VERSION ""

NS_ :

BS_:

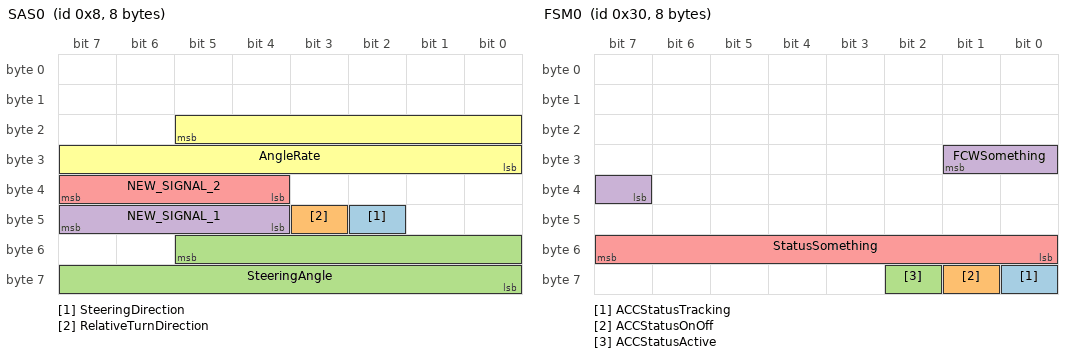
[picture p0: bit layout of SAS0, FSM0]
BO_ 8 SAS0: 8 SAS
 SG_ SteeringDirection : 42|1@0+ (1,0) [0|1] "" XXX
 SG_ RelativeTurnDirection : 43|1@0+ (1,0) [0|1] "" XXX
 SG_ SteeringAngle : 53|14@0+ (0.04395,0) [0|65535] "degrees" XXX
 SG_ NEW_SIGNAL_1 : 47|4@0+ (1,0) [0|15] "" XXX
 SG_ NEW_SIGNAL_2 : 39|4@0+ (1,0) [0|15] "" XXX
 SG_ AngleRate : 21|14@0+ (0.075,0) [0|1500] "deg/S" XXX

BO_ 16 CCButtons: 8 CEM
 SG_ byte0 : 7|8@0+ (1,0) [0|255] "" XXX
 SG_ byte1 : 15|8@0+ (1,0) [0|255] "" XXX
 SG_ byte2 : 23|8@0+ (1,0) [0|255] "" XXX
 SG_ byte3 : 31|8@0+ (1,0) [0|255] "" XXX
 SG_ byte4 : 39|8@0+ (1,0) [0|255] "" XXX
 SG_ byte6 : 55|5@0+ (1,0) [0|31] "" XXX
 SG_ B7b0 : 56|1@0+ (1,0) [0|1] "" XXX
 SG_ B7b1 : 57|1@0+ (1,0) [0|1] "" XXX
 SG_ B7b6 : 62|1@0+ (1,0) [0|1] "" XXX
 SG_ ACCOnOffBtn : 58|1@0+ (1,0) [0|1] "" XXX
 SG_ ACCSetBtn : 63|1@0+ (1,0) [0|1] "" XXX
 SG_ ACCStopBtn : 60|1@0+ (1,0) [0|1] "" XXX
 SG_ ACCResumeBtn : 61|1@0+ (1,0) [0|1] "" XXX
 SG_ ACCMinusBtn : 48|1@0+ (1,0) [0|1] "" XXX
 SG_ TimeGapIncreaseBtn : 49|1@0+ (1,0) [0|1] "" XXX
 SG_ TimeGapDecreaseBtn : 50|1@0+ (1,0) [0|1] "" XXX
 SG_ byte5 : 47|8@0+ (1,0) [0|255] "" XXX
 SG_ B7b3 : 59|1@0+ (1,0) [0|1] "" XXX

BO_ 48 FSM0: 8 FSM
 SG_ ACCStatusTracking : 56|1@0+ (1,0) [0|1] "" XXX
 SG_ ACCStatusOnOff : 57|1@0+ (1,0) [0|1] "" XXX
 SG_ ACCStatusActive : 58|1@0+ (1,0) [0|1] "" XXX
 SG_ FCWSomething : 25|3@0+ (1,0) [0|3] "" XXX
 SG_ StatusSomething : 55|8@0+ (1,0) [0|255] "" XXX

BO_ 64 TCM0: 8 TCM
 SG_ RPMSomething : 42|11@0+ (1,0) [0|2047] "" XXX
 SG_ GearShifter : 46|2@0+ (1,0) [0|3] "" XXX

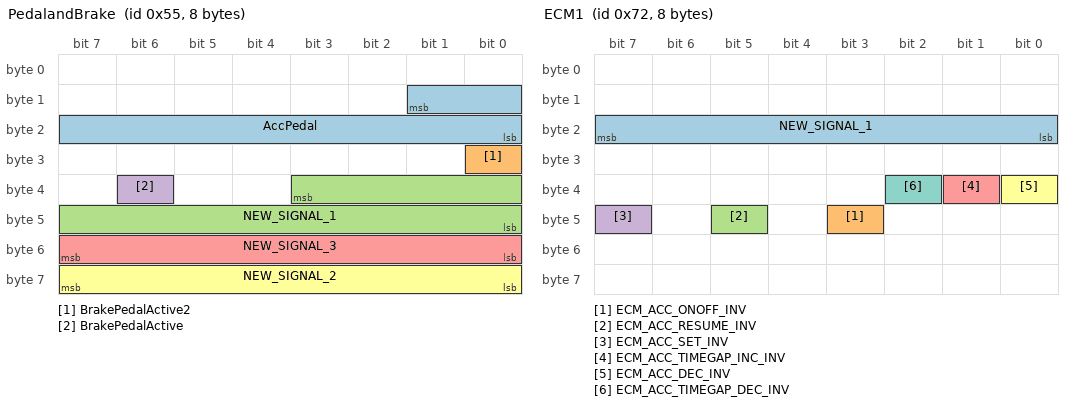
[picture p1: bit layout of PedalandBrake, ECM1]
BO_ 85 PedalandBrake: 8 ECM
 SG_ AccPedal : 9|10@0+ (0.1,0) [0|1023] "%" XXX
 SG_ BrakePedalActive2 : 24|1@0+ (1,0) [0|1] "" XXX
 SG_ NEW_SIGNAL_1 : 35|12@0+ (1,0) [0|4095] "" XXX
 SG_ BrakePedalActive : 38|1@0+ (1,0) [0|1] "" XXX
 SG_ NEW_SIGNAL_3 : 55|8@0+ (1,0) [0|255] "" XXX
 SG_ NEW_SIGNAL_2 : 63|8@0+ (1,0) [0|255] "" XXX

BO_ 101 EngineInfo: 8 XXX
 SG_ NEW_SIGNAL_1 : 17|10@0+ (1,-512) [0|1023] "" XXX
 SG_ EngineSpeed : 52|13@0+ (1,0) [0|1023] "" XXX

BO_ 112 NEW_MSG_4: 8 XXX
 SG_ NEW_SIGNAL_1 : 39|8@0+ (1,0) [0|255] "" XXX

BO_ 114 ECM1: 8 ECM1
 SG_ NEW_SIGNAL_1 : 23|8@0+ (1,0) [0|255] "" XXX
 SG_ ECM_ACC_ONOFF_INV : 43|1@0+ (1,0) [0|1] "" XXX
 SG_ ECM_ACC_RESUME_INV : 45|1@0+ (1,0) [0|1] "" XXX
 SG_ ECM_ACC_SET_INV : 47|1@0+ (1,0) [0|1] "" XXX
 SG_ ECM_ACC_TIMEGAP_INC_INV : 33|1@0+ (1,0) [0|1] "" XXX
 SG_ ECM_ACC_DEC_INV : 32|1@0+ (1,0) [0|1] "" XXX
 SG_ ECM_ACC_TIMEGAP_DEC_INV : 34|1@0+ (1,0) [0|1] "" XXX

BO_ 117 ECM1_2: 8 ECM

BO_ 128 NEW_MSG_5: 8 XXX
 SG_ NEW_SIGNAL_2 : 26|11@0+ (1,0) [0|2047] "" XXX
 SG_ NEW_SIGNAL_1 : 52|13@0+ (1,0) [0|8191] "" XXX

BO_ 176 ECM2: 8 ECM
 SG_ NEW_SIGNAL_1 : 50|11@0+ (1,0) [0|2047] "" XXX
 SG_ NEW_SIGNAL_2 : 47|8@0+ (1,0) [0|63] "" XXX

BO_ 192 Gear: 8 XXX
 SG_ TransmissionGear : 36|3@0+ (1,1) [0|7] "" XXX

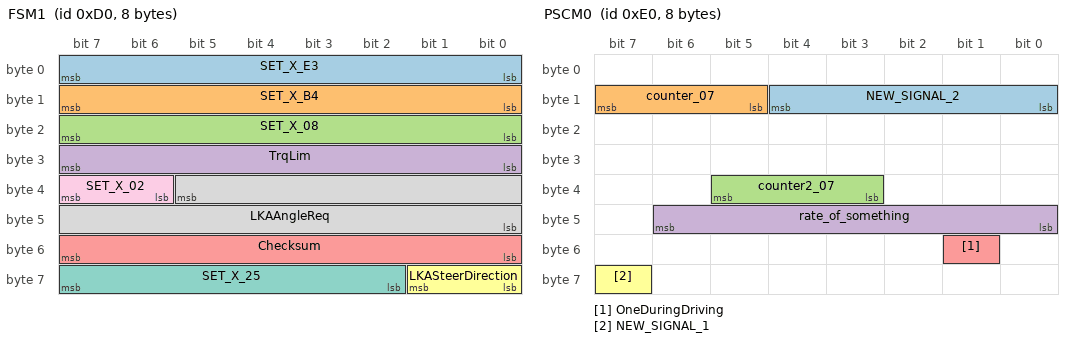
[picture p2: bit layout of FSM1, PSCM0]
BO_ 208 FSM1: 8 FSM
 SG_ SET_X_E3 : 7|8@0+ (1,0) [0|255] "" XXX
 SG_ SET_X_B4 : 15|8@0+ (1,0) [0|255] "" XXX
 SG_ SET_X_08 : 23|8@0+ (1,0) [0|255] "" XXX
 SG_ TrqLim : 31|8@0+ (1,-128) [0|255] "" XXX
 SG_ Checksum : 55|8@0+ (1,0) [0|255] "" XXX
 SG_ LKASteerDirection : 57|2@0+ (1,0) [0|2] "" XXX
 SG_ SET_X_25 : 63|6@0+ (1,0) [0|63] "" XXX
 SG_ LKAAngleReq : 37|14@0+ (0.04395,-360.0384) [-360.0384|359.99445] "degrees" XXX
 SG_ SET_X_02 : 39|2@0+ (1,0) [0|3] "" XXX

BO_ 224 PSCM0: 8 PSCM
 SG_ NEW_SIGNAL_2 : 12|5@0+ (1,0) [0|31] "" XXX
 SG_ counter_07 : 15|3@0+ (1,0) [0|7] "" XXX
 SG_ counter2_07 : 37|3@0+ (1,0) [0|16383] "" XXX
 SG_ rate_of_something : 46|7@0+ (1,0) [0|62] "" XXX
 SG_ OneDuringDriving : 49|1@0+ (1,0) [0|1] "" XXX
 SG_ NEW_SIGNAL_1 : 63|1@0+ (1,0) [0|1] "" XXX

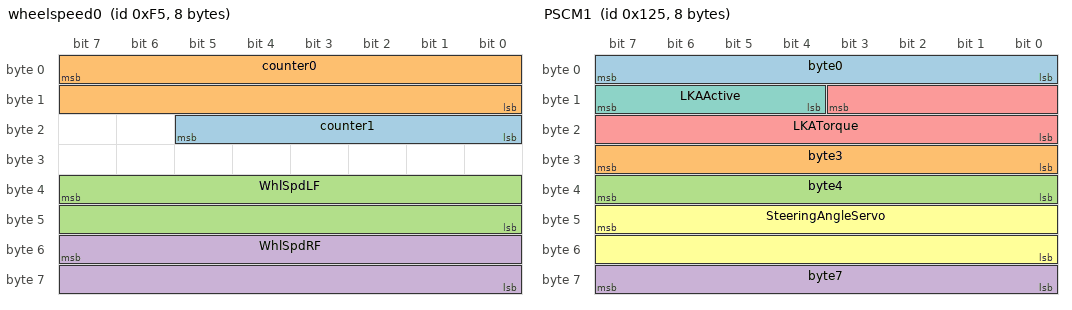
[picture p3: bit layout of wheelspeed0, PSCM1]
BO_ 245 wheelspeed0: 8 BCM
 SG_ counter1 : 21|6@0+ (1,0) [0|65535] "" XXX
 SG_ counter0 : 7|16@0+ (1,0) [0|65535] "" XXX
 SG_ WhlSpdLF : 39|16@0+ (1,0) [0|65535] "" XXX
 SG_ WhlSpdRF : 55|16@0+ (1,0) [0|65535] "" XXX

BO_ 272 SpeedSignal0: 8 XXX
 SG_ VehicleSpeedSignal : 55|16@0+ (0.01,0) [0|65535] "" XXX

BO_ 288 wheel_speed1: 8 BCM
 SG_ WhlSpdLR : 39|16@0+ (1,0) [0|65535] "" XXX
 SG_ WhlSpdRR : 55|16@0+ (1,0) [0|65535] "" XXX

BO_ 293 PSCM1: 8 PSCM
 SG_ byte0 : 7|8@0+ (1,0) [0|255] "" XXX
 SG_ byte3 : 31|8@0+ (1,0) [0|255] "" XXX
 SG_ byte4 : 39|8@0+ (1,0) [0|255] "" XXX
 SG_ byte7 : 63|8@0+ (1,0) [0|255] "" XXX
 SG_ LKATorque : 11|12@0+ (1,-2000) [0|4095] "" XXX
 SG_ SteeringAngleServo : 47|16@0+ (0.04395,-1440.1536) [0|65535] "deg" XXX
 SG_ LKAActive : 15|4@0+ (1,0) [0|15] "" XXX

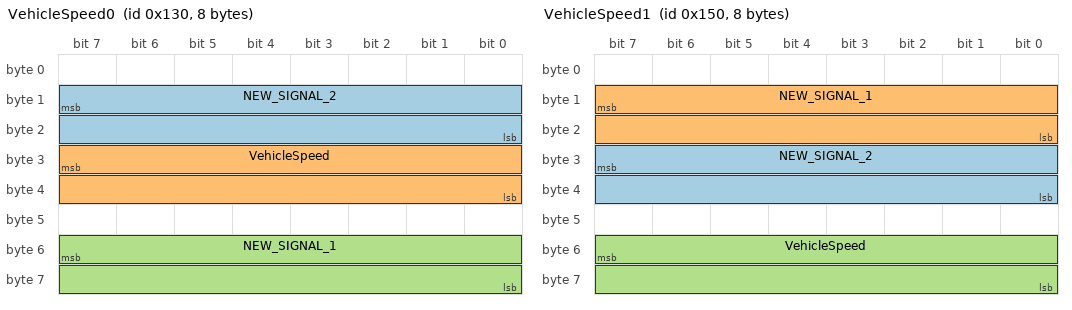
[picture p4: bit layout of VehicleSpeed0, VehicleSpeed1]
BO_ 304 VehicleSpeed0: 8 BCM
 SG_ NEW_SIGNAL_2 : 15|16@0+ (1,0) [0|65535] "" XXX
 SG_ VehicleSpeed : 31|16@0+ (0.01,0) [0|65535] "km/h" XXX
 SG_ NEW_SIGNAL_1 : 55|16@0+ (1,0) [0|65535] "" XXX

BO_ 325 ECM3: 8 ECM

BO_ 336 VehicleSpeed1: 8 BCM
 SG_ NEW_SIGNAL_2 : 31|16@0+ (1,0) [0|65535] "" XXX
 SG_ NEW_SIGNAL_1 : 15|16@0+ (1,0) [0|65535] "" XXX
 SG_ VehicleSpeed : 55|16@0+ (0.01,0) [0|65535] "" XXX

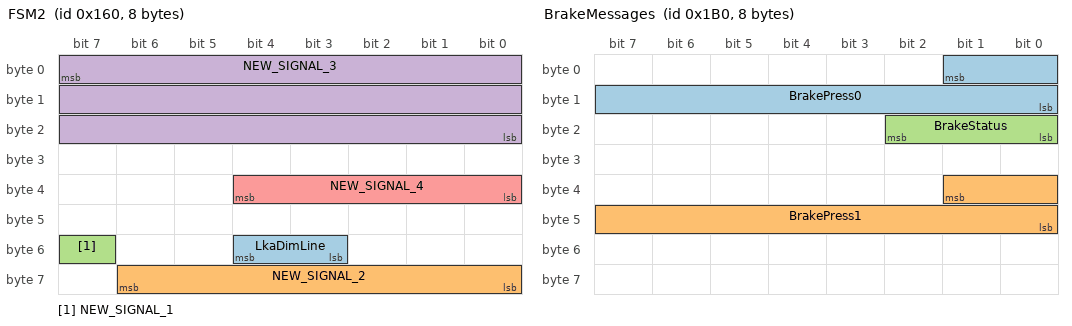
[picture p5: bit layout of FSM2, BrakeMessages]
BO_ 352 FSM2: 8 FSM
 SG_ LkaDimLine : 51|2@1+ (1,0) [0|127] "" XXX
 SG_ NEW_SIGNAL_2 : 56|7@1+ (1,0) [0|255] "" XXX
 SG_ NEW_SIGNAL_1 : 55|1@0+ (1,0) [0|1] "" XXX
 SG_ NEW_SIGNAL_3 : 7|24@0+ (1,0) [0|16777215] "" XXX
 SG_ NEW_SIGNAL_4 : 36|5@0+ (1,0) [0|31] "" XXX

BO_ 432 BrakeMessages: 8 BCM
 SG_ BrakePress0 : 1|10@0+ (1,0) [0|1023] "" XXX
 SG_ BrakePress1 : 33|10@0+ (1,0) [0|1023] "" XXX
 SG_ BrakeStatus : 18|3@0+ (1,0) [0|7] "" XXX

BO_ 464 DIM0: 8 DIM

BO_ 480 BCM0: 8 BCM

BO_ 528 CEM0: 8 CEM

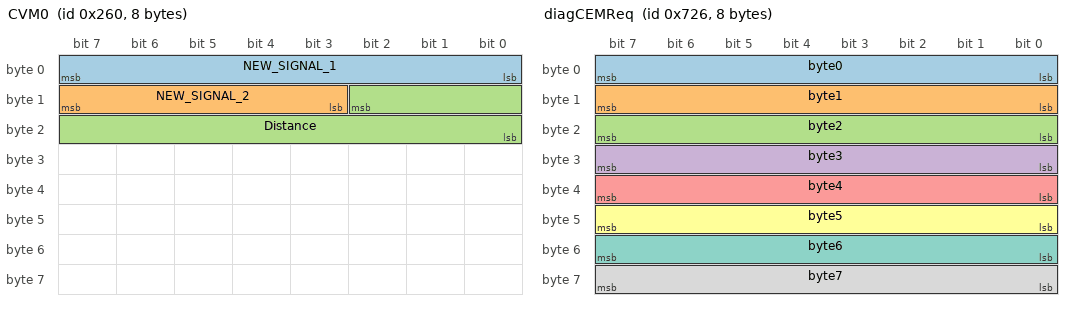
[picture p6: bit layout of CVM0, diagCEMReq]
BO_ 608 CVM0: 8 CVM
 SG_ NEW_SIGNAL_1 : 7|8@0+ (1,0) [0|255] "" XXX
 SG_ NEW_SIGNAL_2 : 15|5@0+ (1,0) [0|32] "" XXX
 SG_ Distance : 10|11@0+ (1,0) [0|2048] "" XXX

BO_ 624 FSM3: 8 FSM
 SG_ NEW_SIGNAL_1 : 23|8@0+ (1,0) [0|255] "" XXX

BO_ 640 FSM4: 8 FSM
 SG_ SpeedTarget : 47|8@0+ (1,0) [0|255] "" XXX
 SG_ NEW_SIGNAL_1 : 49|10@0+ (1,0) [0|255] "" XXX

BO_ 648 SRS0: 8 SRS

BO_ 652 ECM4: 8 ECM

BO_ 656 ECM5: 8 ECM

BO_ 657 ECM6: 8 ECM

BO_ 681 MiscCarInfo: 8 CEM
 SG_ TurnSignal : 1|2@0+ (1,0) [0|3] "" XXX
 SG_ HighBeamOn : 52|1@0+ (1,0) [0|1] "" XX

BO_ 693 ECM7: 8 ECM

BO_ 709 ACC: 8 ECM
 SG_ SpeedTargetACC : 0|9@0+ (0.5,0) [0|511] "" XXX

BO_ 853 FSM5: 8 FSM
 SG_ TargetSpeedOdo : 23|8@0+ (1,0) [0|63] "kph" XXX
 SG_ SpeedSign : 36|5@0+ (5,0) [0|32] "" XXX
 SG_ TextUnderSign : 37|1@0+ (1,0) [0|1] "" XXX
 SG_ NEW_SIGNAL_6 : 39|3@0+ (1,0) [0|3] "" XXX
 SG_ NEW_SIGNAL_5 : 47|8@0+ (1,0) [0|255] "" XXX
 SG_ NEW_SIGNAL_3 : 31|8@0+ (1,0) [0|255] "" XXX
 SG_ LaneMarkingsOdo : 15|4@0+ (1,0) [0|7] "" XXX
 SG_ NEW_SIGNAL_2 : 11|4@0+ (1,0) [0|15] "" XXX
 SG_ NEW_SIGNAL_1 : 7|8@0+ (1,0) [0|255] "" XXX
 SG_ NEW_SIGNAL_4 : 55|16@0+ (1,0) [0|65535] "" XXX

BO_ 864 CEM1: 8 CEM

BO_ 912 DIM1: 8 DIM

BO_ 968 SRS1: 8 SRS
 SG_ PassengerSeatBelt : 22|1@0+ (1,0) [0|1] "" XXX
 SG_ DriverSeatBelt : 19|1@0+ (1,0) [0|1] "" XXX

BO_ 1029 CEMBCM0: 8 CEM

BO_ 1344 NEW_MSG_1: 8 XXX
 SG_ NEW_SIGNAL_1 : 4|13@0+ (1,0) [0|8191] "" XXX

BO_ 1830 diagCEMReq: 8 XXX
 SG_ byte0 : 7|8@0+ (1,0) [0|255] "" XXX
 SG_ byte1 : 15|8@0+ (1,0) [0|255] "" XXX
 SG_ byte2 : 23|8@0+ (1,0) [0|255] "" XXX
 SG_ byte3 : 31|8@0+ (1,0) [0|255] "" XXX
 SG_ byte4 : 39|8@0+ (1,0) [0|255] "" XXX
 SG_ byte5 : 47|8@0+ (1,0) [0|255] "" XXX
 SG_ byte6 : 55|8@0+ (1,0) [0|255] "" XXX
 SG_ byte7 : 63|8@0+ (1,0) [0|255] "" XXX

BO_ 1838 diagCEMResp: 8 XXX
 SG_ byte03 : 7|32@0+ (1,0) [0|4294967295] "" XXX
 SG_ byte47 : 39|32@0+ (1,0) [0|4294967295] "" XXX

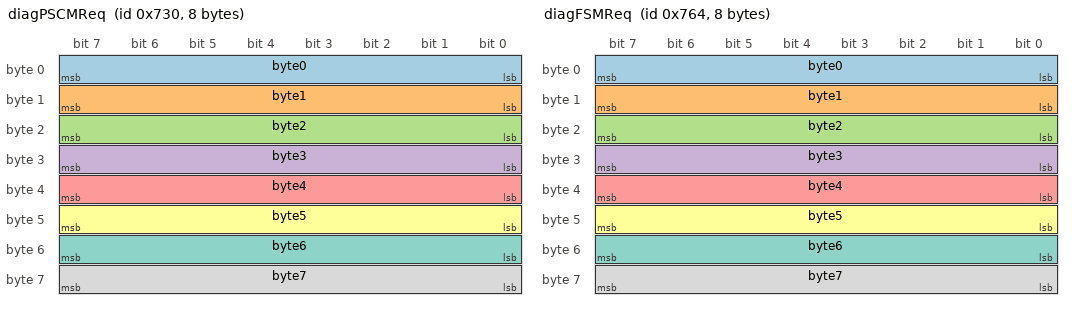
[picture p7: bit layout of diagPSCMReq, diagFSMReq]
BO_ 1840 diagPSCMReq: 8 XXX
 SG_ byte0 : 7|8@0+ (1,0) [0|255] "" XXX
 SG_ byte1 : 15|8@0+ (1,0) [0|255] "" XXX
 SG_ byte2 : 23|8@0+ (1,0) [0|255] "" XXX
 SG_ byte3 : 31|8@0+ (1,0) [0|255] "" XXX
 SG_ byte4 : 39|8@0+ (1,0) [0|255] "" XXX
 SG_ byte5 : 47|8@0+ (1,0) [0|255] "" XXX
 SG_ byte6 : 55|8@0+ (1,0) [0|255] "" XXX
 SG_ byte7 : 63|8@0+ (1,0) [0|255] "" XXX

BO_ 1848 diagPSCMResp: 8 XXX
 SG_ byte03 : 7|32@0+ (1,0) [0|4294967295] "" XXX
 SG_ byte47 : 39|32@0+ (1,0) [0|4294967295] "" XXX

BO_ 1892 diagFSMReq: 8 XXX
 SG_ byte0 : 7|8@0+ (1,0) [0|255] "" XXX
 SG_ byte1 : 15|8@0+ (1,0) [0|255] "" XXX
 SG_ byte2 : 23|8@0+ (1,0) [0|255] "" XXX
 SG_ byte3 : 31|8@0+ (1,0) [0|255] "" XXX
 SG_ byte4 : 39|8@0+ (1,0) [0|255] "" XXX
 SG_ byte5 : 47|8@0+ (1,0) [0|255] "" XXX
 SG_ byte6 : 55|8@0+ (1,0) [0|255] "" XXX
 SG_ byte7 : 63|8@0+ (1,0) [0|255] "" XXX

BO_ 1900 diagFSMResp: 8 XXX
 SG_ byte03 : 7|32@0+ (1,0) [0|4294967295] "" XXX
 SG_ byte47 : 39|32@0+ (1,0) [0|4294967295] "" XXX

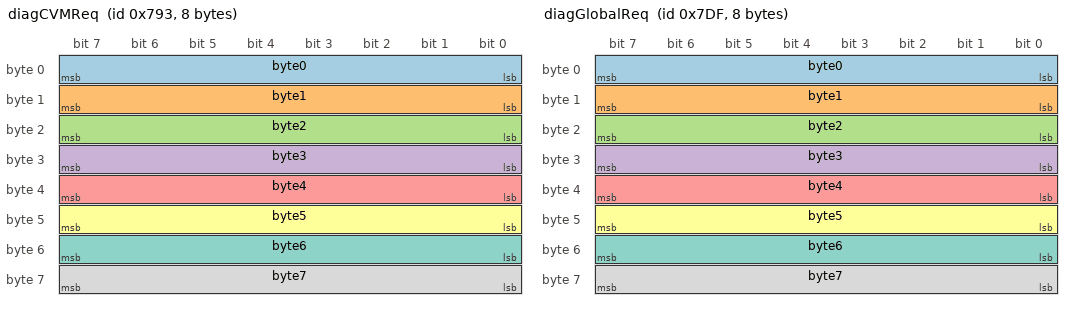
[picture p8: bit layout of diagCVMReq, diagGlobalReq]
BO_ 1939 diagCVMReq: 8 XXX
 SG_ byte0 : 7|8@0+ (1,0) [0|255] "" XXX
 SG_ byte1 : 15|8@0+ (1,0) [0|255] "" XXX
 SG_ byte2 : 23|8@0+ (1,0) [0|255] "" XXX
 SG_ byte3 : 31|8@0+ (1,0) [0|255] "" XXX
 SG_ byte4 : 39|8@0+ (1,0) [0|255] "" XXX
 SG_ byte5 : 47|8@0+ (1,0) [0|255] "" XXX
 SG_ byte6 : 55|8@0+ (1,0) [0|255] "" XXX
 SG_ byte7 : 63|8@0+ (1,0) [0|255] "" XXX

BO_ 1947 diagCVMResp: 8 XXX
 SG_ byte03 : 7|32@0+ (1,0) [0|4294967295] "" XXX
 SG_ byte47 : 39|32@0+ (1,0) [0|4294967295] "" XXX

BO_ 2015 diagGlobalReq: 8 XXX
 SG_ byte0 : 7|8@0+ (1,0) [0|255] "" XXX
 SG_ byte1 : 15|8@0+ (1,0) [0|255] "" XXX
 SG_ byte2 : 23|8@0+ (1,0) [0|255] "" XXX
 SG_ byte3 : 31|8@0+ (1,0) [0|255] "" XXX
 SG_ byte4 : 39|8@0+ (1,0) [0|255] "" XXX
 SG_ byte5 : 47|8@0+ (1,0) [0|255] "" XXX
 SG_ byte6 : 55|8@0+ (1,0) [0|255] "" XXX
 SG_ byte7 : 63|8@0+ (1,0) [0|255] "" XXX

BU_: XXX

CM_ SG_ 1104 DRIVER_SEAT_BELT_ONOFF "0 - on , 1 = off";
CM_ SG_ 1056 DOOR_RL_STATUS "04 - RL - open";
CM_ SG_ 1056 DOOR_FL_STATUS "28 - FL open , 38 - FR";
CM_ SG_ 1056 RIGHT_SIGNAL_STATUS "R,L shows at same time means hazard";
CM_ SG_ 832 TRANS_MODE "AT - 85 / MT - 8D";
CM_ SG_ 832 TRANS_GEAR_POS "R-7 , 0 - N";
CM_ SG_ 821 CRUSE_ONOFF "Cruse Switch";
CM_ SG_ 821 CRUSE_ENABLED "Cruse enabled";
CM_ SG_ 821 THROTTLE_PEDAL_POS "Real Pedal Pos";
CM_ SG_ 821 THROTTLE_POS "Throttle Pos for Cruse Mode";
CM_ SG_ 906 ABS_UNDEF1 "ABS force";
CM_ SG_ 906 SPEED_FL "used for car speed in dash board";
VAL_ 513 STATE 5 "FAULT_TIMEOUT" 4 "FAULT_STARTUP" 3 "FAULT_SCE" 2 "FAULT_SEND" 1 "FAULT_BAD_CHECKSUM" 0 "NO_FAULT" ;

VAL_ 295 GEAR 0 "P" 1 "R" 2 "N" 3 "D" 4 "B";
VAL_ 466 CRUISE_STATE 11 "timer_3sec" 10 "adaptive click down" 9 "adaptive click up" 8 "adaptive engaged" 7 "standstill" 6 "non-adaptive click up" 5 "non-adaptive click down" 4 "non-adaptive hold down" 3 "non-adaptive hold up" 2 "non-adaptive being engaged" 1 "non-adaptive engaged" 0 "off";
VAL_ 467 LOW_SPEED_LOCKOUT 2 "low speed locked" 1 "ok";
VAL_ 467 PCM_FOLLOW_DISTANCE 1 "far" 2 "medium" 3 "close";
VAL_ 614 STATE 3 "enabled" 1 "disabled";
VAL_ 614 DIRECTION_CMD 3 "right" 2 "center" 1 "left";
VAL_ 643 STATE 0 "normal" 1 "adaptive_cruise_control" 3 "emergency_braking";
VAL_ 835 ACC_TYPE 2 "permanent low speed lockout" 1 "ok";
VAL_ 835 ACC_MALFUNCTION 1 "faulted" 0 "ok";
VAL_ 835 ACC_CUT_IN 1 "CUT-IN Detected" 0 "clear";
VAL_ 835 ALLOW_LONG_PRESS 2 "set speed increase by 5 speed units regardless" 1 "set speed increase by 1 speed unit on short press, 5 speed units on long press";
VAL_ 865 CLUTCH_RELEASED 0 "clutch pressed any amount" 1 "clutch released"
VAL_ 921 CRUISE_CONTROL_STATE 2 "disabled" 11 "hold" 10 "hold_waiting_user_cmd" 6 "enabled" 5 "faulted";
VAL_ 956 SPORT_ON 0 "off" 1 "on";
VAL_ 956 GEAR 0 "D" 1 "S" 8 "N" 16 "R" 32 "P";
VAL_ 956 SPORT_GEAR_ON 0 "off" 1 "on";
VAL_ 956 SPORT_GEAR 1 "S1" 2 "S2" 3 "S3" 4 "S4" 5 "S5" 6 "S6";
VAL_ 956 ECON_ON 0 "off" 1 "on";
VAL_ 956 B_GEAR_ENGAGED 0 "off" 1 "on";
VAL_ 956 DRIVE_ENGAGED 0 "off" 1 "on";
VAL_ 1005 REVERSE_CAMERA_GUIDELINES 3 "No guidelines" 2 "Static guidelines" 1 "Active guidelines";
VAL_ 1009 PCM_FOLLOW_DISTANCE 1 "far" 2 "medium" 3 "close";
VAL_ 1041 PCS_INDICATOR 2 "PCS Faulted" 1 "PCS Turned Off By User" 0 "PCS Enabled";
VAL_ 1041 PCS_SENSITIVITY 64 "high sensitivity"  128 "mid sensitivity" 192 "low sensitivity" 0 "off";
VAL_ 1042 LDA_ALERT 3 "hold with continuous beep" 2 "LDA unavailable" 1 "hold" 0 "none";
VAL_ 1042 BARRIERS 3 "left" 2 "right" 1 "both" 0 "none";
VAL_ 1042 RIGHT_LINE 3 "orange" 2 "faded" 1 "solid" 0 "none";
VAL_ 1042 LKAS_STATUS 1 "on" 0 "off";
VAL_ 1042 LEFT_LINE 3 "orange" 2 "faded" 1 "solid" 0 "none";
VAL_ 1042 LDA_ON_MESSAGE 2 "Lane Departure Alert Turned ON, Steering Assist Inactive" 1 "Lane Departure Alert Turned ON, Steering Assist Active" 0 "clear";
VAL_ 1042 LDA_SA_TOGGLE  2 "steering assist off" 1 "steering assist on";
VAL_ 1042 LDA_SENSITIVITY 2 "standard" 1 "high" 0 "undefined";
VAL_ 1042 LDA_MESSAGES 4 "lda unavailable at this speed" 1 "lda unavailable below approx 50km/h" 0 "ok";
VAL_ 1042 LDA_FRONT_CAMERA_BLOCKED 1 "lda unavailable" 0 "ok";
VAL_ 1042 TAKE_CONTROL 1 "take control" 0 "ok";
VAL_ 1042 LANE_SWAY_WARNING 3 "ok" 2 "orange please take a break" 1 "prompt would you like to take a break" 0 "ok";
VAL_ 1042 LANE_SWAY_BUZZER 3 "ok" 2 "beep twice" 1 "beep twice" 0 "ok";
VAL_ 1161 TSGN1 1 "speed sign" 0 "none";
VAL_ 1161 TSGN2 1 "speed sign" 0 "none";
VAL_ 1161 SPLSGN2 15 "conditional blank" 4 "wet road" 5 "rain" 0 "none";
VAL_ 1162 TSGN3 0 "none" 1 "speed sign" 2 "0 unlimited" 7 "unlimited" 16 "highway" 17 "no highway" 18 "motorway" 19 "no motorway" 20 "in city" 21 "outside city" 22 "pedestrian area" 23 "no pedestrian area" 65 "no overtaking left" 66 "no overtaking right" 67 "overtaking allowed again" 81 "no right turn" 97 "stop" 105 "yield" 113 "stop" 114 "yield us" 129 "no entry" 138 "no entry tss2" 145 "do not enter";
VAL_ 1162 SPLSGN3 15 "conditional blank" 4 "wet road" 5 "rain" 0 "none";
VAL_ 1552 METER_SLIDER_LOW_BRIGHTNESS 1 "Low brightness mode, footwell lights off" 0 "Normal mode, footwell lights on";
VAL_ 1552 METER_SLIDER_DIMMED 1 "Dimmed" 0 "Not Dimmed";
VAL_ 1552 UNITS 1 "km (km/L)" 2 "km (L/100km)" 3 "miles (MPG US)" 4 "miles (MPG Imperial)";
VAL_ 1553 UNITS 1 "km" 2 "miles";
VAL_ 1556 TURN_SIGNALS 3 "none" 2 "right" 1 "left";
VAL_ 1592 LOCK_STATUS 0 "locked" 1 "unlocked";

VAL_ 610 IPAS_STATE 5 "override" 3 "enabled" 1 "disabled";
